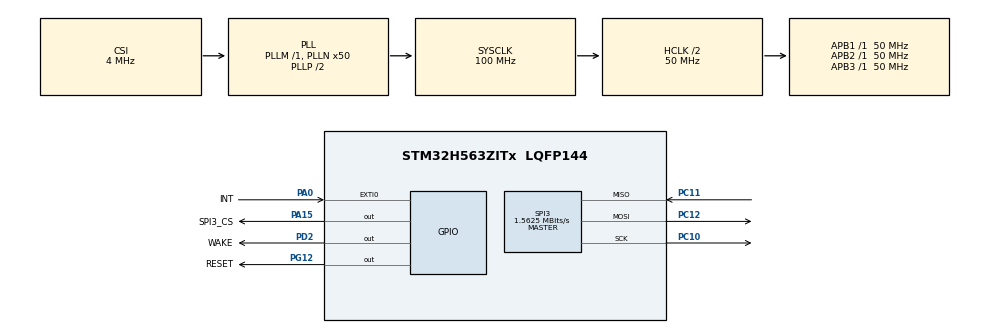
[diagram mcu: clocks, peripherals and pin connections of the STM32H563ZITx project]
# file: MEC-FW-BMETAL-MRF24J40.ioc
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CORTEX_M33_NS.userName=CORTEX_M33
Mcu.Family=STM32H5
Mcu.Name=STM32H563ZITx
Mcu.Package=LQFP144
NVIC.EXTI0_IRQn=true\:0\:0\:false\:false\:true\:true\:true\:true
NVIC.PriorityGroup=NVIC_PRIORITYGROUP_4
PA0.GPIO_Label=INT
PA0.GPIO_ModeDefaultEXTI=GPIO_MODE_IT_FALLING
PA0.Signal=GPXTI0
PA13(JTMS/SWDIO).Mode=Trace_Asynchronous_SW
PA13(JTMS/SWDIO).Signal=DEBUG_JTMS-SWDIO
PA14(JTCK/SWCLK).Mode=Trace_Asynchronous_SW
PA14(JTCK/SWCLK).Signal=DEBUG_JTCK-SWCLK
PA15(JTDI).GPIO_Label=SPI3_CS
PA15(JTDI).GPIO_Speed=GPIO_SPEED_FREQ_VERY_HIGH
PA15(JTDI).PinState=GPIO_PIN_SET
PA15(JTDI).Signal=GPIO_Output
PB3(JTDO/TRACESWO).Mode=Trace_Asynchronous_SW
PB3(JTDO/TRACESWO).Signal=DEBUG_JTDO-SWO
PC10.Mode=Full_Duplex_Master
PC10.Signal=SPI3_SCK
PC11.Mode=Full_Duplex_Master
PC11.Signal=SPI3_MISO
PC12.Mode=Full_Duplex_Master
PC12.Signal=SPI3_MOSI
PD2.GPIO_Label=WAKE
PD2.Signal=GPIO_Output
PG12.GPIO_Label=RESET
PG12.PinState=GPIO_PIN_SET
PG12.Signal=GPIO_Output
ProjectManager.HeapSize=0x200
ProjectManager.StackSize=0x400
ProjectManager.TargetToolchain=STM32CubeIDE
RCC.ADCFreq_Value=50000000
RCC.AHBCLKDivider=RCC_SYSCLK_DIV2
RCC.AHBFreq_Value=50000000
RCC.APB1Freq_Value=50000000
RCC.APB1TimFreq_Value=50000000
RCC.APB2Freq_Value=50000000
RCC.APB2TimFreq_Value=50000000
RCC.APB3Freq_Value=50000000
RCC.CSI_VALUE=4000000
RCC.CortexFreq_Value=50000000
RCC.EPOD_VALUE=4000000
RCC.HCLKFreq_Value=50000000
RCC.HSE_VALUE=25000000
RCC.HSI48_VALUE=48000000
RCC.HSI_VALUE=64000000
RCC.LSE_VALUE=32768
RCC.LSIRC_VALUE=32000
RCC.PLLFRACN=0
RCC.PLLN=50
RCC.SYSCLKFreq_VALUE=100000000
RCC.SYSCLKSource=RCC_SYSCLKSOURCE_PLLCLK
RCC.USBFreq_Value=48000000
RCC.VCOOutputFreq_Value=200000000
SPI3.BaudRatePrescaler=SPI_BAUDRATEPRESCALER_64
SPI3.CalculateBaudRate=1.5625 MBits/s
SPI3.DataSize=SPI_DATASIZE_8BIT
SPI3.Direction=SPI_DIRECTION_2LINES
SPI3.Mode=SPI_MODE_MASTER
SPI3.NSSPMode=SPI_NSS_PULSE_DISABLE
SPI3.VirtualType=VM_MASTER
VP_BOOTPATH_VS_BOOTPATH.Mode=BP_Activate
VP_CORTEX_M33_NS_VS_Hclk.Mode=Hclk_Mode
VP_ICACHE_VS_ENABLE_ICACHE_MEMORY.Mode=Memoryregions
VP_ICACHE_VS_ICACHE.Mode=DirectMappedCache
VP_MEMORYMAP_VS_MEMORYMAP.Mode=CurAppReg
VP_PWR_VS_LPOM.Mode=PowerOptimisation
VP_PWR_VS_SECSignals.Mode=Security/Privilege
board=custom

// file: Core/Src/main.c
/* USER CODE BEGIN Header */
/**
  ******************************************************************************
  * @file           : main.c
  * @brief          : Main program body
  ******************************************************************************
  * @attention
  *
  * Copyright (c) 2026 STMicroelectronics.
  * All rights reserved.
  *
  * This software is licensed under terms that can be found in the LICENSE file
  * in the root directory of this software component.
  * If no LICENSE file comes with this software, it is provided AS-IS.
  *
  ******************************************************************************
  */
/* USER CODE END Header */
#include "main.h"

/* USER CODE BEGIN Includes */
#include "mrf24j40_task.h"
/* USER CODE END Includes */

SPI_HandleTypeDef hspi3;

void SystemClock_Config(void);
static void MX_GPIO_Init(void);
static void MX_ICACHE_Init(void);
static void MX_SPI3_Init(void);

int main(void)
{

  /* MCU Configuration--------------------------------------------------------*/

  /* Reset of all peripherals, Initializes the Flash interface and the Systick. */
  HAL_Init();

  /* Configure the system clock */
  SystemClock_Config();

  /* Initialize all configured peripherals */
  MX_GPIO_Init();
  MX_ICACHE_Init();
  MX_SPI3_Init();
  /* USER CODE BEGIN 2 */

  app_task();

  /* USER CODE END 2 */

  /* Infinite loop */
  while (1)
  {

  }
}

void SystemClock_Config(void)
{
  RCC_OscInitTypeDef RCC_OscInitStruct = {0};
  RCC_ClkInitTypeDef RCC_ClkInitStruct = {0};

  /** Configure the main internal regulator output voltage
  */
  __HAL_PWR_VOLTAGESCALING_CONFIG(PWR_REGULATOR_VOLTAGE_SCALE3);

  while(!__HAL_PWR_GET_FLAG(PWR_FLAG_VOSRDY)) {}

  /** Initializes the RCC Oscillators according to the specified parameters
  * in the RCC_OscInitTypeDef structure.
  */
  RCC_OscInitStruct.OscillatorType = RCC_OSCILLATORTYPE_CSI;
  RCC_OscInitStruct.CSIState = RCC_CSI_ON;
  RCC_OscInitStruct.CSICalibrationValue = RCC_CSICALIBRATION_DEFAULT;
  RCC_OscInitStruct.PLL.PLLState = RCC_PLL_ON;
  RCC_OscInitStruct.PLL.PLLSource = RCC_PLL1_SOURCE_CSI;
  RCC_OscInitStruct.PLL.PLLM = 1;
  RCC_OscInitStruct.PLL.PLLN = 50;
  RCC_OscInitStruct.PLL.PLLP = 2;
  RCC_OscInitStruct.PLL.PLLQ = 2;
  RCC_OscInitStruct.PLL.PLLR = 2;
  RCC_OscInitStruct.PLL.PLLRGE = RCC_PLL1_VCIRANGE_2;
  RCC_OscInitStruct.PLL.PLLVCOSEL = RCC_PLL1_VCORANGE_WIDE;
  RCC_OscInitStruct.PLL.PLLFRACN = 0;
  if (HAL_RCC_OscConfig(&RCC_OscInitStruct) != HAL_OK)
  {
    Error_Handler();
  }

  /** Initializes the CPU, AHB and APB buses clocks
  */
  RCC_ClkInitStruct.ClockType = RCC_CLOCKTYPE_HCLK|RCC_CLOCKTYPE_SYSCLK
                              |RCC_CLOCKTYPE_PCLK1|RCC_CLOCKTYPE_PCLK2
                              |RCC_CLOCKTYPE_PCLK3;
  RCC_ClkInitStruct.SYSCLKSource = RCC_SYSCLKSOURCE_PLLCLK;
  RCC_ClkInitStruct.AHBCLKDivider = RCC_SYSCLK_DIV2;
  RCC_ClkInitStruct.APB1CLKDivider = RCC_HCLK_DIV1;
  RCC_ClkInitStruct.APB2CLKDivider = RCC_HCLK_DIV1;
  RCC_ClkInitStruct.APB3CLKDivider = RCC_HCLK_DIV1;

  if (HAL_RCC_ClockConfig(&RCC_ClkInitStruct, FLASH_LATENCY_4) != HAL_OK)
  {
    Error_Handler();
  }

  /** Configure the programming delay
  */
  __HAL_FLASH_SET_PROGRAM_DELAY(FLASH_PROGRAMMING_DELAY_2);
}

static void MX_ICACHE_Init(void)
{

  /** Enable instruction cache in 1-way (direct mapped cache)
  */
  if (HAL_ICACHE_ConfigAssociativityMode(ICACHE_1WAY) != HAL_OK)
  {
    Error_Handler();
  }
  if (HAL_ICACHE_Enable() != HAL_OK)
  {
    Error_Handler();
  }

}

static void MX_SPI3_Init(void)
{

  /* SPI3 parameter configuration*/
  hspi3.Instance = SPI3;
  hspi3.Init.Mode = SPI_MODE_MASTER;
  hspi3.Init.Direction = SPI_DIRECTION_2LINES;
  hspi3.Init.DataSize = SPI_DATASIZE_8BIT;
  hspi3.Init.CLKPolarity = SPI_POLARITY_LOW;
  hspi3.Init.CLKPhase = SPI_PHASE_1EDGE;
  hspi3.Init.NSS = SPI_NSS_SOFT;
  hspi3.Init.BaudRatePrescaler = SPI_BAUDRATEPRESCALER_64;
  hspi3.Init.FirstBit = SPI_FIRSTBIT_MSB;
  hspi3.Init.TIMode = SPI_TIMODE_DISABLE;
  hspi3.Init.CRCCalculation = SPI_CRCCALCULATION_DISABLE;
  hspi3.Init.CRCPolynomial = 0x7;
  hspi3.Init.NSSPMode = SPI_NSS_PULSE_DISABLE;
  hspi3.Init.NSSPolarity = SPI_NSS_POLARITY_LOW;
  hspi3.Init.FifoThreshold = SPI_FIFO_THRESHOLD_01DATA;
  hspi3.Init.MasterSSIdleness = SPI_MASTER_SS_IDLENESS_00CYCLE;
  hspi3.Init.MasterInterDataIdleness = SPI_MASTER_INTERDATA_IDLENESS_00CYCLE;
  hspi3.Init.MasterReceiverAutoSusp = SPI_MASTER_RX_AUTOSUSP_DISABLE;
  hspi3.Init.MasterKeepIOState = SPI_MASTER_KEEP_IO_STATE_DISABLE;
  hspi3.Init.IOSwap = SPI_IO_SWAP_DISABLE;
  hspi3.Init.ReadyMasterManagement = SPI_RDY_MASTER_MANAGEMENT_INTERNALLY;
  hspi3.Init.ReadyPolarity = SPI_RDY_POLARITY_HIGH;
  if (HAL_SPI_Init(&hspi3) != HAL_OK)
  {
    Error_Handler();
  }

}

static void MX_GPIO_Init(void)
{
  GPIO_InitTypeDef GPIO_InitStruct = {0};

  /* GPIO Ports Clock Enable */
  __HAL_RCC_GPIOA_CLK_ENABLE();
  __HAL_RCC_GPIOC_CLK_ENABLE();
  __HAL_RCC_GPIOD_CLK_ENABLE();
  __HAL_RCC_GPIOG_CLK_ENABLE();
  __HAL_RCC_GPIOB_CLK_ENABLE();

  /*Configure GPIO pin Output Level */
  HAL_GPIO_WritePin(SPI3_CS_GPIO_Port, SPI3_CS_Pin, GPIO_PIN_SET);

  /*Configure GPIO pin Output Level */
  HAL_GPIO_WritePin(WAKE_GPIO_Port, WAKE_Pin, GPIO_PIN_RESET);

  /*Configure GPIO pin Output Level */
  HAL_GPIO_WritePin(RESET_GPIO_Port, RESET_Pin, GPIO_PIN_SET);

  /*Configure GPIO pin : INT_Pin */
  GPIO_InitStruct.Pin = INT_Pin;
  GPIO_InitStruct.Mode = GPIO_MODE_IT_FALLING;
  GPIO_InitStruct.Pull = GPIO_NOPULL;
  HAL_GPIO_Init(INT_GPIO_Port, &GPIO_InitStruct);

  /*Configure GPIO pin : SPI3_CS_Pin */
  GPIO_InitStruct.Pin = SPI3_CS_Pin;
  GPIO_InitStruct.Mode = GPIO_MODE_OUTPUT_PP;
  GPIO_InitStruct.Pull = GPIO_NOPULL;
  GPIO_InitStruct.Speed = GPIO_SPEED_FREQ_VERY_HIGH;
  HAL_GPIO_Init(SPI3_CS_GPIO_Port, &GPIO_InitStruct);

  /*Configure GPIO pin : WAKE_Pin */
  GPIO_InitStruct.Pin = WAKE_Pin;
  GPIO_InitStruct.Mode = GPIO_MODE_OUTPUT_PP;
  GPIO_InitStruct.Pull = GPIO_NOPULL;
  GPIO_InitStruct.Speed = GPIO_SPEED_FREQ_LOW;
  HAL_GPIO_Init(WAKE_GPIO_Port, &GPIO_InitStruct);

  /*Configure GPIO pin : RESET_Pin */
  GPIO_InitStruct.Pin = RESET_Pin;
  GPIO_InitStruct.Mode = GPIO_MODE_OUTPUT_PP;
  GPIO_InitStruct.Pull = GPIO_NOPULL;
  GPIO_InitStruct.Speed = GPIO_SPEED_FREQ_LOW;
  HAL_GPIO_Init(RESET_GPIO_Port, &GPIO_InitStruct);

  /* EXTI interrupt init*/
  HAL_NVIC_SetPriority(EXTI0_IRQn, 0, 0);
  HAL_NVIC_EnableIRQ(EXTI0_IRQn);

}

void Error_Handler(void)
{
  __disable_irq();
  while (1)
  {
  }
}
